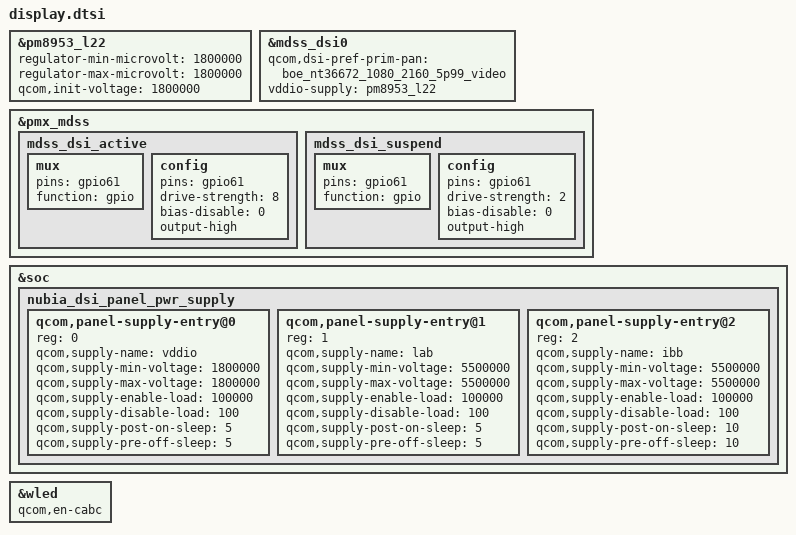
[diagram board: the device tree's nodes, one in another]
/*
 * Copyright (c) 2015-2016, The Linux Foundation. All rights reserved.
 *
 * This program is free software; you can redistribute it and/or modify
 * it under the terms of the GNU General Public License version 2 and
 * only version 2 as published by the Free Software Foundation.
 *
 * This program is distributed in the hope that it will be useful,
 * but WITHOUT ANY WARRANTY; without even the implied warranty of
 * MERCHANTABILITY or FITNESS FOR A PARTICULAR PURPOSE.  See the
 * GNU General Public License for more details.
 */

/*---------------------------------------------------------------------------
 * This file is autogenerated file using gcdb parser. Please do not edit it.
 * Update input XML file to add a new entry or update variable in this file
 * VERSION = "1.0"
 *---------------------------------------------------------------------------*/
#include "../nubia_panel/nubia_panel.dtsi"


&pm8953_l22 {
	regulator-min-microvolt = <1800000>;
	regulator-max-microvolt = <1800000>;
	qcom,init-voltage = <1800000>;
};

&mdss_dsi0 {
	qcom,dsi-pref-prim-pan = <&boe_nt36672_1080_2160_5p99_video>;

	/* pin config */
	/delete-property/ qcom,platform-enable-gpio;
	/delete-property/ qcom,platform-bklight-en-gpio;

	/*power config*/
	/delete-property/ vdd-supply;
	vddio-supply = <&pm8953_l22>;
};


&pmx_mdss {
	/delete-node/ mdss_dsi_active;
	mdss_dsi_active: mdss_dsi_active {
			 mux {
				 /*gpio60,lcd reset*/
				pins = "gpio61";
				function = "gpio";
			};

			 config {
				pins = "gpio61";
				drive-strength = <8>; /* 8 mA */
				bias-disable = <0>; /* no pull */
				output-high;
			};
		 };
	/delete-node/ mdss_dsi_suspend;
	mdss_dsi_suspend: mdss_dsi_suspend {
			  mux {
				pins = "gpio61";
				function = "gpio";
			  };

			  config {
				pins = "gpio61";
				drive-strength = <2>; /* 2 mA */
				bias-disable = <0>; /* no pull */
				output-high;
			 };
		  };
};

&soc {
        nubia_dsi_panel_pwr_supply: nubia_dsi_panel_pwr_supply {
                #address-cells = <1>;
                #size-cells = <0>;

                qcom,panel-supply-entry@0 {
                        reg = <0>;
                        qcom,supply-name = "vddio";
                        qcom,supply-min-voltage = <1800000>;
                        qcom,supply-max-voltage = <1800000>;
                        qcom,supply-enable-load = <100000>;
                        qcom,supply-disable-load = <100>;
			qcom,supply-post-on-sleep = <5>;
			qcom,supply-pre-off-sleep = <5>;
                };

                qcom,panel-supply-entry@1 {
                        reg = <1>;
                        qcom,supply-name = "lab";
                        qcom,supply-min-voltage = <5500000>;
                        qcom,supply-max-voltage = <5500000>;
                        qcom,supply-enable-load = <100000>;
                        qcom,supply-disable-load = <100>;
			qcom,supply-post-on-sleep = <5>;
			qcom,supply-pre-off-sleep = <5>;
                };

                qcom,panel-supply-entry@2 {
                        reg = <2>;
                        qcom,supply-name = "ibb";
                        qcom,supply-min-voltage = <5500000>;
                        qcom,supply-max-voltage = <5500000>;
                        qcom,supply-enable-load = <100000>;
                        qcom,supply-disable-load = <100>;
                        qcom,supply-post-on-sleep = <10>;
			qcom,supply-pre-off-sleep = <10>;
                };
        };
};

&wled {
        /delete-property/ qcom,en-ext-pfet-sc-pro;
	qcom,en-cabc;
};
